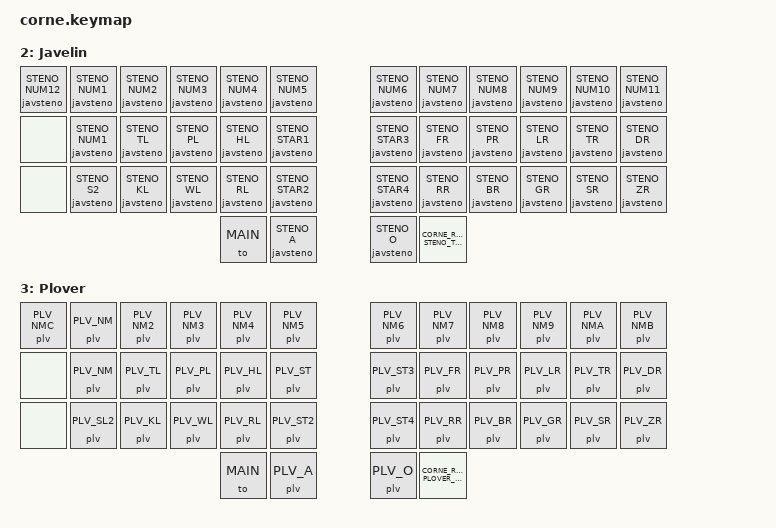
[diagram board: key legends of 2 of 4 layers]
#include <behaviors.dtsi>
#include <dt-bindings/zmk/keys.h>
#include <dt-bindings/zmk/bt.h>
#include <behaviors/javelin_steno.dtsi>
#include <behaviors/plover_hid.dtsi>
#include <dt-bindings/zmk/hid-io/plover_hid.h>
#include <dt-bindings/zmk/javelin_steno.h>
#include <dt-bindings/zmk/javelin_steno_layers.h>

// The firmware recognises these layers by ID. Keep the layer order below in
// step with javelin_steno_layers.h.
#define MAIN JAVELIN_LAYER_MAIN
#define SYM_NUM JAVELIN_LAYER_SYM_NUM
#define STENO JAVELIN_LAYER_STENO
#define PLOVER_HID JAVELIN_LAYER_PLOVER_HID

#ifndef CORNE_RIGHT_SYMBOL_THUMBS
#define CORNE_RIGHT_SYMBOL_THUMBS &none &kp N0 &none
#endif

#ifndef CORNE_LEFT_MAIN_THUMBS
#define CORNE_LEFT_MAIN_THUMBS &kp LCMD &mo SYM_NUM &kp BSPC
#endif

#ifndef CORNE_RIGHT_MAIN_THUMBS
#define CORNE_RIGHT_MAIN_THUMBS &kp SPACE &to PLOVER_HID &to STENO
#endif

#ifndef CORNE_RIGHT_STENO_THUMBS
#define CORNE_RIGHT_STENO_THUMBS &javsteno STENO_E &javsteno STENO_U &to PLOVER_HID
#endif

#ifndef CORNE_RIGHT_PLOVER_THUMBS
#define CORNE_RIGHT_PLOVER_THUMBS &plv PLV_E &plv PLV_U &to STENO
#endif

#ifndef CORNE_LEFT_SYMBOL_ROW_0
// Voyager LED positions Q/W/R select or clear host Bluetooth profiles.
#define CORNE_LEFT_SYMBOL_ROW_0 &kp LG(LA(ESC)) &bt BT_SEL 0 &bt BT_SEL 1 &kp UP &bt BT_CLR &none
#endif

#ifndef CORNE_STENO_SPARE_KEY
// The unused key left of the Lapwing # key (the one above S) on the steno layer.
#define CORNE_STENO_SPARE_KEY &none
#endif

#ifndef CORNE_LEFT_SYMBOL_ROW_1
#define CORNE_LEFT_SYMBOL_ROW_1 &none &none &kp LEFT &kp DOWN &kp RIGHT &none
#endif

/ {
    chosen {
        zmk,physical-layout = &foostan_corne_6col_layout;
    };
};

&sk {
    release-after-ms = <2000>;
    quick-release;
};

/ {
    behaviors {
        ht: tap_first {
            compatible = "zmk,behavior-tap-first";
            display-name = "Tap / Hold";
            #binding-cells = <2>;
            bindings = <&ht_impl>;
        };
        ht_impl: hold_tap {
            compatible = "zmk,behavior-hold-tap";
            #binding-cells = <2>;
            flavor = "tap-preferred";
            tapping-term-ms = <200>;
            quick-tap-ms = <125>;
            require-prior-idle-ms = <125>;
            bindings = <&kp>, <&kp>;
        };
    };

    keymap {
        compatible = "zmk,keymap";

        main_layer {
            display-name = "Qwerty";
            // ht parameters: tap first, hold second. Editing shortcuts use Command.
            bindings = <
&ht TAB ESC  &ht Q LBKT   &ht W RBKT   &ht E LBRC   &ht R RBRC   &ht T SQT       &ht Y MINUS &ht U AMPS &ht I STAR     &ht O LG(F)   &ht P LG(LS(N4)) &kp DEL
&kp LCTRL    &ht A LG(A)  &ht S LG(S)  &ht D LPAR   &ht F RPAR   &ht G DQT       &ht H UNDER &ht J EXCL &ht K HASH     &ht L TILDE   &ht SEMI RET     &kp RET
&kp LSHIFT   &ht Z LG(Z)  &ht X LG(X)  &ht C LG(C)  &ht V LG(V)  &ht B GRAVE     &ht N EQUAL &ht M AT   &ht COMMA DLLR &ht DOT CARET &ht FSLH BSLH    &sk LSHIFT
                                      CORNE_LEFT_MAIN_THUMBS                CORNE_RIGHT_MAIN_THUMBS
            >;
        };

        sym_num_layer {
            display-name = "Numpad";
            bindings = <
CORNE_LEFT_SYMBOL_ROW_0                                                        &kp KP_PLUS &kp N7 &kp N8 &kp N9 &kp BSPC &kp BSPC
CORNE_LEFT_SYMBOL_ROW_1                                                        &kp MINUS   &kp N4 &kp N5 &kp N6 &kp RET  &kp RET
&kp LS(LEFT)   &none        &none       &kp SPACE &none      &none           &kp EQUAL   &kp N1 &kp N2 &kp N3 &kp DOT  &trans
                                      &trans &trans &trans                 CORNE_RIGHT_SYMBOL_THUMBS
            >;
        };

        steno_layer {
            display-name = "Javelin";
            // Onboard Javelin.
            bindings = <
&javsteno STENO_NUM12 &javsteno STENO_NUM1  &javsteno STENO_NUM2 &javsteno STENO_NUM3 &javsteno STENO_NUM4 &javsteno STENO_NUM5    &javsteno STENO_NUM6 &javsteno STENO_NUM7 &javsteno STENO_NUM8 &javsteno STENO_NUM9 &javsteno STENO_NUM10 &javsteno STENO_NUM11
CORNE_STENO_SPARE_KEY &javsteno STENO_NUM1 &javsteno STENO_TL  &javsteno STENO_PL  &javsteno STENO_HL  &javsteno STENO_STAR1     &javsteno STENO_STAR3 &javsteno STENO_FR  &javsteno STENO_PR  &javsteno STENO_LR  &javsteno STENO_TR  &javsteno STENO_DR
&none        &javsteno STENO_S2 &javsteno STENO_KL  &javsteno STENO_WL  &javsteno STENO_RL  &javsteno STENO_STAR2    &javsteno STENO_STAR4 &javsteno STENO_RR  &javsteno STENO_BR  &javsteno STENO_GR  &javsteno STENO_SR  &javsteno STENO_ZR
                                      &to MAIN &javsteno STENO_A &javsteno STENO_O               CORNE_RIGHT_STENO_THUMBS
            >;
        };
        plover_hid_layer {
            display-name = "Plover";
            // Voyager geometry; distinct Plover HID indices for every steno key.
            bindings = <
&plv PLV_NMC &plv PLV_NM  &plv PLV_NM2 &plv PLV_NM3 &plv PLV_NM4 &plv PLV_NM5    &plv PLV_NM6 &plv PLV_NM7 &plv PLV_NM8 &plv PLV_NM9 &plv PLV_NMA &plv PLV_NMB
&none        &plv PLV_NM  &plv PLV_TL  &plv PLV_PL  &plv PLV_HL  &plv PLV_ST     &plv PLV_ST3 &plv PLV_FR  &plv PLV_PR  &plv PLV_LR  &plv PLV_TR  &plv PLV_DR
&none        &plv PLV_SL2 &plv PLV_KL  &plv PLV_WL  &plv PLV_RL  &plv PLV_ST2    &plv PLV_ST4 &plv PLV_RR  &plv PLV_BR  &plv PLV_GR  &plv PLV_SR  &plv PLV_ZR
                                      &to MAIN &plv PLV_A &plv PLV_O               CORNE_RIGHT_PLOVER_THUMBS
            >;
        };
    };
};
